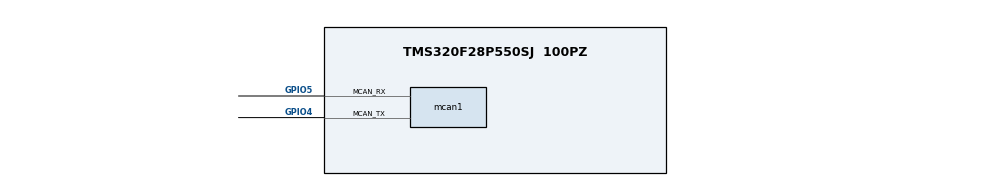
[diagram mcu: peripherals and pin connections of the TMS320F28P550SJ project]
/**
 * AI AGENTS: Do not edit this file directly. There is no validation or error feedback when
 * editing manually — mistakes will be silent until the file is loaded in SysConfig.
 * Use the SysConfig MCP server instead to make changes with immediate error reporting.
 *
 * These arguments were used when this file was generated. They will be automatically applied on subsequent loads
 * via the GUI or CLI. Run CLI with '--help' for additional information on how to override these arguments.
 * @cliArgs --device "F28P55x" --part "F28P55x_100PZ" --package "100PZ" --context "system" --product "C2000WARE@26.01.00.00"
 * @v2CliArgs --device "TMS320F28P550SJ" --package "100PZ" --variant "TMS320F28P550SJ9" --context "system" --product "C2000WARE@26.01.00.00"
 * @versions {"tool":"1.28.0+4696"}
 */

/**
 * Import the modules used in this configuration.
 */
const adc            = scripting.addModule("/driverlib/adc.js", {}, false);
const adc1           = adc.addInstance();
const adc2           = adc.addInstance();
const adc3           = adc.addInstance();
const analog         = scripting.addModule("/driverlib/analog.js", {}, false);
const analog1        = analog.addInstance();
const device_support = scripting.addModule("/driverlib/device_support.js");
const epwm           = scripting.addModule("/driverlib/epwm.js", {}, false);
const epwm1          = epwm.addInstance();
const epwm2          = epwm.addInstance();
const mcan           = scripting.addModule("/driverlib/mcan.js", {}, false);
const mcan1          = mcan.addInstance();
const spi            = scripting.addModule("/driverlib/spi.js", {}, false);
const spi1           = spi.addInstance();

/**
 * Write custom configuration values to the imported modules.
 */
adc1.$name                          = "myADCA";
adc1.adcClockPrescaler              = "ADC_CLK_DIV_2_0";
adc1.interruptPulseMode             = "ADC_PULSE_END_OF_CONV";
adc1.socHighPriorityMode            = "ADC_PRI_ALL_HIPRI";
adc1.enabledSOCs                    = ["ADC_SOC_NUMBER0","ADC_SOC_NUMBER1","ADC_SOC_NUMBER2"];
adc1.enabledInts                    = ["ADC_INT_NUMBER1"];
adc1.enabledPPBs                    = ["ADC_PPB_NUMBER1","ADC_PPB_NUMBER2","ADC_PPB_NUMBER3"];
adc1.soc0Name                       = "SOC0_Udc";
adc1.soc0Trigger                    = "ADC_TRIGGER_EPWM1_SOCA";
adc1.soc0SampleWindow               = 12;
adc1.soc1Name                       = "SOC1_Vin";
adc1.soc1Channel                    = "ADC_CH_ADCIN4";
adc1.soc1Trigger                    = "ADC_TRIGGER_EPWM1_SOCA";
adc1.soc1SampleWindow               = 12;
adc1.soc2Name                       = "SOC2_Idc";
adc1.soc2Channel                    = "ADC_CH_ADCIN12";
adc1.soc2Trigger                    = "ADC_TRIGGER_EPWM1_SOCA";
adc1.soc2SampleWindow               = 12;
adc1.enableInterrupt1               = true;
adc1.interrupt1SOCSource            = "ADC_INT_TRIGGER_EOC2";
adc1.enableInterrupt1ContinuousMode = true;
adc1.ppb1HighTripLimit              = 2000;
adc1.ppb1LowTripLimit               = -2000;
adc1.ppb1ReferenceOffset            = 200;
adc1.ppb2SOCNumber                  = "ADC_SOC_NUMBER1";
adc1.ppb2HighTripLimit              = 4000;
adc1.ppb2ReferenceOffset            = 2048;
adc1.ppb3SOCNumber                  = "ADC_SOC_NUMBER2";
adc1.ppb3ReferenceOffset            = 2048;

adc2.$name                          = "myADCB";
adc2.adcBase                        = "ADCB_BASE";
adc2.adcClockPrescaler              = "ADC_CLK_DIV_2_0";
adc2.interruptPulseMode             = "ADC_PULSE_END_OF_CONV";
adc2.socHighPriorityMode            = "ADC_PRI_ALL_HIPRI";
adc2.enabledSOCs                    = ["ADC_SOC_NUMBER0","ADC_SOC_NUMBER1"];
adc2.enabledInts                    = ["ADC_INT_NUMBER1"];
adc2.enabledPPBs                    = ["ADC_PPB_NUMBER1","ADC_PPB_NUMBER2"];
adc2.soc0Name                       = "SOC0_Ia";
adc2.soc0Channel                    = "ADC_CH_ADCIN1";
adc2.soc0Trigger                    = "ADC_TRIGGER_EPWM2_SOCA";
adc2.soc0SampleWindow               = 120;
adc2.soc1Name                       = "SOC1_Ib";
adc2.soc1Channel                    = "ADC_CH_ADCIN7";
adc2.soc1Trigger                    = "ADC_TRIGGER_EPWM2_SOCA";
adc2.soc1SampleWindow               = 12;
adc2.enableInterrupt1               = true;
adc2.interrupt1SOCSource            = "ADC_INT_TRIGGER_EOC1";
adc2.enableInterrupt1ContinuousMode = true;
adc2.ppb1ReferenceOffset            = 2048;
adc2.ppb2SOCNumber                  = "ADC_SOC_NUMBER1";
adc2.ppb2ReferenceOffset            = 2048;

adc3.$name                          = "myADCC";
adc3.adcBase                        = "ADCC_BASE";
adc3.adcClockPrescaler              = "ADC_CLK_DIV_2_0";
adc3.interruptPulseMode             = "ADC_PULSE_END_OF_CONV";
adc3.enabledSOCs                    = ["ADC_SOC_NUMBER0"];
adc3.enabledInts                    = ["ADC_INT_NUMBER1"];
adc3.soc0Channel                    = "ADC_CH_ADCIN12";
adc3.soc0Trigger                    = "ADC_TRIGGER_EPWM2_SOCA";
adc3.soc0SampleWindow               = 512;
adc3.enableInterrupt1               = true;
adc3.enableInterrupt1ContinuousMode = true;

analog1.$name                                              = "myANALOGPinMux0";
adc1.analog                                                = analog1;
adc2.analog                                                = analog1;
adc3.analog                                                = analog1;
analog1.analog["a2, b6, c9, pga1_inp, gpio224Pin"].$assign = "A2, B6, C9, PGA1_INP, GPIO224";

const divider4       = system.clockTree["MCANACLKDIV"];
divider4.divideValue = 1;

epwm1.$name   = "myEPWM1";
epwm1.useCase = "CUSTOM";

epwm2.$name   = "myEPWM2";
epwm2.useCase = "CUSTOM";

mcan1.loopbackMode             = false;
mcan1.enableInterrupt          = true;
mcan1.interruptLine            = ["MCAN_INTR_LINE_NUM_0"];
mcan1.registerInterruptLine0   = true;
mcan1.rxBufElemSize            = "0";
mcan1.rxFIFO0OpMode            = "1";
mcan1.rxFIFO1OpMode            = "1";
mcan1.lse                      = 0;
mcan1.stdFilts                 = 1;
mcan1.rrfs                     = true;
mcan1.rrfe                     = true;
mcan1.rxFIFO0ElemSize          = "0";
mcan1.interruptLine0Flag       = ["MCAN_IR_RF0N_MASK"];
mcan1.$name                    = "myMCANA";
mcan1.tdcEnable                = true;
mcan1.additionalCoreConfig     = true;
mcan1.timeoutSelect            = "MCAN_TIMEOUT_SELECT_RX_FIFO0";
mcan1.anfe                     = "2";
mcan1.anfs                     = "2";
mcan1.stdFiltsUsed             = [0];
mcan1.emulationEnable          = true;
mcan1.darEnable                = true;
mcan1.nomRatePrescalar         = 5;
mcan1.txpEnable                = true;
mcan1.interruptFlags           = ["MCAN_IR_BO_MASK","MCAN_IR_EP_MASK","MCAN_IR_PED_MASK","MCAN_IR_RF0N_MASK","MCAN_IR_TCF_MASK"];
mcan1.registerInterruptLine1   = true;
mcan1.interruptLine1Flag       = ["MCAN_IR_BO_MASK","MCAN_IR_EP_MASK","MCAN_IR_PED_MASK"];
mcan1.tdcConfig_tdco           = 33;
mcan1.dataRatePrescalar        = 1;
mcan1.dataTimeSeg1             = 21;
mcan1.dataTimeSeg2             = 6;
mcan1.dataSynchJumpWidth       = 5;
mcan1.nomTimeSeg1              = 17;
mcan1.nomTimeSeg2              = 5;
mcan1.nomSynchJumpWidth        = 4;
mcan1.rxFIFO0size              = 10;
mcan1.txBufNum                 = 5;
mcan1.useCalcStartingAddress   = true;
mcan1.mcan.$assign             = "MCANA";
mcan1.mcan.mcan_rxPin.$assign  = "GPIO5";
mcan1.mcan.mcan_txPin.$assign  = "GPIO4";
mcan1.mcanInt0.enableInterrupt = true;
mcan1.stdFilt0.$name           = "stdFilt1";
mcan1.stdFilt0.sfid1           = 2;
mcan1.stdFilt0.sfid2           = 2;
mcan1.stdFilt0.sfec            = "MCAN_STDFILTEC_FIFO0";
mcan1.mcanInt1.enableInterrupt = true;

spi1.$name       = "mySPIB";
spi1.useCase     = "CUSTOM";
spi1.spi.$assign = "SPIB";

/**
 * Pinmux solution for unlocked pins/peripherals. This ensures that minor changes to the automatic solver in a future
 * version of the tool will not impact the pinmux you originally saw.  These lines can be completely deleted in order to
 * re-solve from scratch.
 */
analog1.analog.$suggestSolution                                       = "ANALOG";
analog1.analog["a0, b15, c15, daca_outPin"].$suggestSolution          = "A0, B15, C15, DACA_OUT";
analog1.analog["a3, b9, c7, pga1_inmPin"].$suggestSolution            = "A3, B9, C7, PGA1_INM";
analog1.analog["a4, b8Pin"].$suggestSolution                          = "A4, B8";
analog1.analog.a5Pin.$suggestSolution                                 = "A5";
analog1.analog["a6, d14, e14, gpio228Pin"].$suggestSolution           = "A6, D14, E14, GPIO228";
analog1.analog["a7, b30, c3, d12, e30Pin"].$suggestSolution           = "A7, B30, C3, D12, E30";
analog1.analog.a8Pin.$suggestSolution                                 = "A8";
analog1.analog["a9, gpio227Pin"].$suggestSolution                     = "A9, GPIO227";
analog1.analog["a10, b1, c10, gpio230Pin"].$suggestSolution           = "A10, B1, C10, GPIO230";
analog1.analog["a11, b10, c0, pga2_outPin"].$suggestSolution          = "A11, B10, C0, PGA2_OUT";
analog1.analog["a12, c5Pin"].$suggestSolution                         = "A12, C5";
analog1.analog["a14, b14, c4, pga1_outPin"].$suggestSolution          = "A14, B14, C4, PGA1_OUT";
analog1.analog["a16, b16, c16, gpio28Pin"].$suggestSolution           = "A16, B16, C16, GPIO28";
analog1.analog["a17, b17, c17, gpio20Pin"].$suggestSolution           = "A17, B17, C17, GPIO20";
analog1.analog["a18, b18, c18, gpio21Pin"].$suggestSolution           = "A18, B18, C18, GPIO21";
analog1.analog["a19, b19, c19, gpio13Pin"].$suggestSolution           = "A19, B19, C19, GPIO13";
analog1.analog["a20, b20, c20, gpio12Pin"].$suggestSolution           = "A20, B20, C20, GPIO12";
analog1.analog["a24, d0, e0, gpio11Pin"].$suggestSolution             = "A24, D0, E0, GPIO11";
analog1.analog["a25, d3, e3, gpio17Pin"].$suggestSolution             = "A25, D3, E3, GPIO17";
analog1.analog["b0, c11, gpio253Pin"].$suggestSolution                = "B0, C11, GPIO253";
analog1.analog["b2, c6, e12, gpio226Pin"].$suggestSolution            = "B2, C6, E12, GPIO226";
analog1.analog["b3, pga2_inp, gpio242Pin"].$suggestSolution           = "B3, PGA2_INP, GPIO242";
analog1.analog["b4, c8, gpio236Pin"].$suggestSolution                 = "B4, C8, GPIO236";
analog1.analog["b5, d15, e15, pga3_outPin"].$suggestSolution          = "B5, D15, E15, PGA3_OUT";
analog1.analog["b11, d16, e16, pga3_inmPin"].$suggestSolution         = "B11, D16, E16, PGA3_INM";
analog1.analog["b12, c2, pga2_inmPin"].$suggestSolution               = "B12, C2, PGA2_INM";
analog1.analog["b24, d1, e1, gpio33Pin"].$suggestSolution             = "B24, D1, E1, GPIO33";
analog1.analog["b25, d4, e4, gpio24Pin"].$suggestSolution             = "B25, D4, E4, GPIO24";
analog1.analog["c1, e11, pga3_inpPin"].$suggestSolution               = "C1, E11, PGA3_INP";
analog1.analog["c14, gpio247Pin"].$suggestSolution                    = "C14, GPIO247";
analog1.analog["c24, d2, e2, gpio16Pin"].$suggestSolution             = "C24, D2, E2, GPIO16";
analog1.analog["d20, e20, vrefhiPin"].$suggestSolution                = "D20, E20, VREFHI";
analog1.analog["a13, b13, c13, d13, e13, vrefloPin"].$suggestSolution = "A13, B13, C13, D13, E13, VREFLO";
analog1.analog["a1, b7, d11, cmp1_daclPin"].$suggestSolution          = "A1, B7, D11, CMP1_DACL";
epwm1.epwm.$suggestSolution                                           = "EPWM2";
epwm2.epwm.$suggestSolution                                           = "EPWM1";
